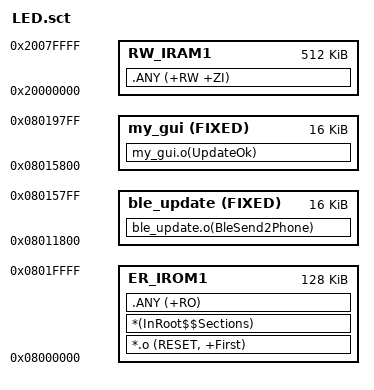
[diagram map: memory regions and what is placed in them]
; *************************************************************
; *** Scatter-Loading Description File generated by uVision ***
; *************************************************************

LR_IROM1 0x08000000 0x00020000  {    ; load region size_region
  ER_IROM1 0x08000000 0x00020000  {  ; load address = execution address
   *.o (RESET, +First)
   *(InRoot$$Sections)
   .ANY (+RO)
  } 
  ble_update 0x08011800 FIXED 0x4000
  {
	ble_update.o(BleSend2Phone)
  }
  my_gui 0x08015800 FIXED 0x4000
  {
	my_gui.o(UpdateOk)
  }
  RW_IRAM1 0x20000000 0x00080000  {  ; RW data
   .ANY (+RW +ZI)
  }
}

 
